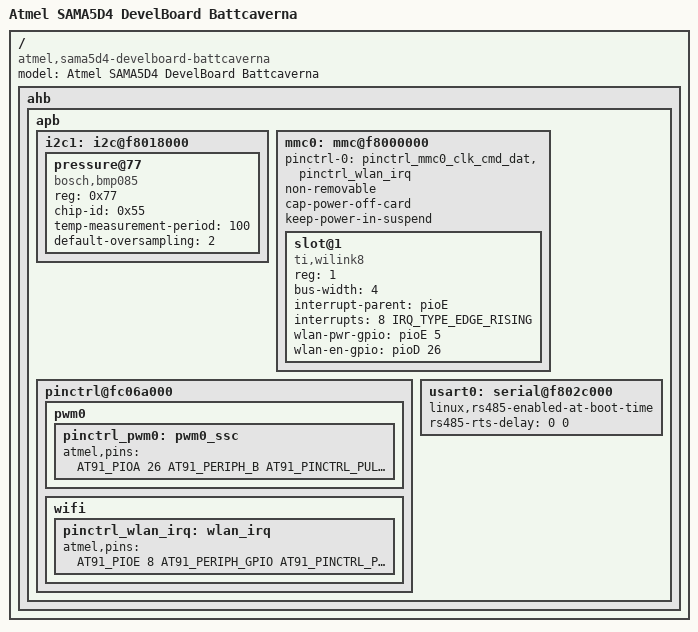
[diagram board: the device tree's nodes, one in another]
/*
 * at91-sama5d4_develboard_battcaverna.dts
 *
 *  Copyright (C) 2017 Develer,
 *                2017 Pietro Lorefice <pietro@develer.com>
 *                2017 Francesco Sacchi <batt@develer.com>
 *
 * This file is dual-licensed: you can use it either under the terms
 * of the GPL or the X11 license, at your option. Note that this dual
 * licensing only applies to this file, and not this project as a
 * whole.
 *
 *  a) This file is free software; you can redistribute it and/or
 *     modify it under the terms of the GNU General Public License as
 *     published by the Free Software Foundation; either version 2 of the
 *     License, or (at your option) any later version.
 *
 *     This file is distributed in the hope that it will be useful,
 *     but WITHOUT ANY WARRANTY; without even the implied warranty of
 *     MERCHANTABILITY or FITNESS FOR A PARTICULAR PURPOSE.  See the
 *     GNU General Public License for more details.
 *
 * Or, alternatively,
 *
 *  b) Permission is hereby granted, free of charge, to any person
 *     obtaining a copy of this software and associated documentation
 *     files (the "Software"), to deal in the Software without
 *     restriction, including without limitation the rights to use,
 *     copy, modify, merge, publish, distribute, sublicense, and/or
 *     sell copies of the Software, and to permit persons to whom the
 *     Software is furnished to do so, subject to the following
 *     conditions:
 *
 *     The above copyright notice and this permission notice shall be
 *     included in all copies or substantial portions of the Software.
 *
 *     THE SOFTWARE IS PROVIDED "AS IS", WITHOUT WARRANTY OF ANY KIND,
 *     EXPRESS OR IMPLIED, INCLUDING BUT NOT LIMITED TO THE WARRANTIES
 *     OF MERCHANTABILITY, FITNESS FOR A PARTICULAR PURPOSE AND
 *     NONINFRINGEMENT. IN NO EVENT SHALL THE AUTHORS OR COPYRIGHT
 *     HOLDERS BE LIABLE FOR ANY CLAIM, DAMAGES OR OTHER LIABILITY,
 *     WHETHER IN AN ACTION OF CONTRACT, TORT OR OTHERWISE, ARISING
 *     FROM, OUT OF OR IN CONNECTION WITH THE SOFTWARE OR THE USE OR
 *     OTHER DEALINGS IN THE SOFTWARE.
 */
#include "at91-sama5d4_develboard.dts"

/ {
	model = "Atmel SAMA5D4 DevelBoard Battcaverna";
	compatible = "atmel,sama5d4-develboard-battcaverna", "atmel,sama5d4-develboard", "atmel,sama5d4", "atmel,sama5";

	ahb {
		apb {
			i2c1: i2c@f8018000 {
				status = "okay";

				pressure@77 {
					compatible = "bosch,bmp085";
					reg = <0x77>;
					chip-id = <0x55>;
					temp-measurement-period = <100>;
					default-oversampling = <2>;
				};
			};

			mmc0: mmc@f8000000 {
				pinctrl-names = "default";
				pinctrl-0 = <&pinctrl_mmc0_clk_cmd_dat &pinctrl_wlan_irq>;
				status = "okay";

				non-removable;
				cap-power-off-card;
				keep-power-in-suspend;

				slot@1 {
					compatible = "ti,wilink8";
					reg = <1>;
					bus-width = <4>;
					interrupt-parent = <&pioE>;
					interrupts = <8 IRQ_TYPE_EDGE_RISING>;
					wlan-pwr-gpio = <&pioE 5 GPIO_ACTIVE_HIGH>;
					wlan-en-gpio = <&pioD 26 GPIO_ACTIVE_HIGH>;
					status = "okay";
				};
			};

			pinctrl@fc06a000 {
				pwm0 {
					pinctrl_pwm0: pwm0_ssc {
						atmel,pins = <
							AT91_PIOA 26 AT91_PERIPH_B AT91_PINCTRL_PULL_DOWN /* PWMH0 */
							AT91_PIOA 28 AT91_PERIPH_B AT91_PINCTRL_PULL_DOWN /* PWMH1 */
							AT91_PIOC 2  AT91_PERIPH_B AT91_PINCTRL_PULL_DOWN /* PWMH3 */
						>;
					};
				};
				wifi {
					pinctrl_wlan_irq: wlan_irq {
						atmel,pins = <
							AT91_PIOE 8 AT91_PERIPH_GPIO AT91_PINCTRL_PULL_DOWN  /* WLAN_IRQ */
						>;
					};
				};
			};

			usart0: serial@f802c000 {
				status = "okay";
				linux,rs485-enabled-at-boot-time;
				rs485-rts-delay = <0 0>;
			};
		};
	};

};

